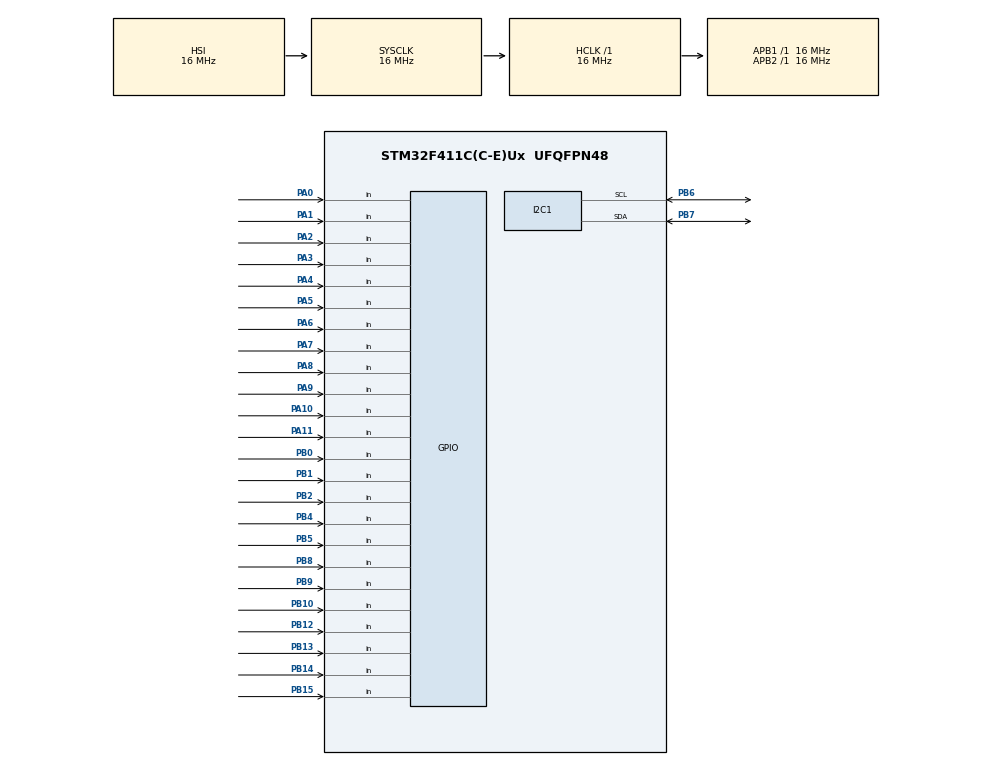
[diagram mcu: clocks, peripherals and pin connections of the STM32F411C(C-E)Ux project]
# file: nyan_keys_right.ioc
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I2C1.I2C_Mode=I2C_Fast
Mcu.Family=STM32F4
Mcu.Name=STM32F411C(C-E)Ux
Mcu.Package=UFQFPN48
NVIC.PriorityGroup=NVIC_PRIORITYGROUP_4
PA0-WKUP.GPIO_PuPd=GPIO_PULLUP
PA0-WKUP.Signal=GPIO_Input
PA1.GPIO_PuPd=GPIO_PULLUP
PA1.Signal=GPIO_Input
PA10.GPIO_PuPd=GPIO_PULLUP
PA10.Signal=GPIO_Input
PA11.GPIO_PuPd=GPIO_PULLUP
PA11.Signal=GPIO_Input
PA13.Mode=Serial_Wire
PA13.Signal=SYS_JTMS-SWDIO
PA14.Mode=Serial_Wire
PA14.Signal=SYS_JTCK-SWCLK
PA2.GPIO_PuPd=GPIO_PULLUP
PA2.Signal=GPIO_Input
PA3.GPIO_PuPd=GPIO_PULLUP
PA3.Signal=GPIO_Input
PA4.GPIO_PuPd=GPIO_PULLUP
PA4.Signal=GPIO_Input
PA5.GPIO_PuPd=GPIO_PULLUP
PA5.Signal=GPIO_Input
PA6.GPIO_PuPd=GPIO_PULLUP
PA6.Signal=GPIO_Input
PA7.GPIO_PuPd=GPIO_PULLUP
PA7.Signal=GPIO_Input
PA8.GPIO_PuPd=GPIO_PULLUP
PA8.Signal=GPIO_Input
PA9.GPIO_PuPd=GPIO_PULLUP
PA9.Signal=GPIO_Input
PB0.GPIO_PuPd=GPIO_PULLUP
PB0.Signal=GPIO_Input
PB1.GPIO_PuPd=GPIO_PULLUP
PB1.Signal=GPIO_Input
PB10.GPIO_PuPd=GPIO_PULLUP
PB10.Signal=GPIO_Input
PB12.GPIO_PuPd=GPIO_PULLUP
PB12.Signal=GPIO_Input
PB13.GPIO_PuPd=GPIO_PULLUP
PB13.Signal=GPIO_Input
PB14.GPIO_PuPd=GPIO_PULLUP
PB14.Signal=GPIO_Input
PB15.GPIO_PuPd=GPIO_PULLUP
PB15.Signal=GPIO_Input
PB2.GPIO_PuPd=GPIO_PULLUP
PB2.Signal=GPIO_Input
PB4.GPIO_PuPd=GPIO_PULLUP
PB4.Signal=GPIO_Input
PB5.GPIO_PuPd=GPIO_PULLUP
PB5.Signal=GPIO_Input
PB6.Mode=I2C
PB6.Signal=I2C1_SCL
PB7.Mode=I2C
PB7.Signal=I2C1_SDA
PB8.GPIO_PuPd=GPIO_PULLUP
PB8.Signal=GPIO_Input
PB9.GPIO_PuPd=GPIO_PULLUP
PB9.Signal=GPIO_Input
PC14-OSC32_IN.Mode=LSE-External-Oscillator
PC14-OSC32_IN.Signal=RCC_OSC32_IN
PC15-OSC32_OUT.Mode=LSE-External-Oscillator
PC15-OSC32_OUT.Signal=RCC_OSC32_OUT
PH0\ -\ OSC_IN.Mode=HSE-External-Oscillator
PH0\ -\ OSC_IN.Signal=RCC_OSC_IN
PH1\ -\ OSC_OUT.Mode=HSE-External-Oscillator
PH1\ -\ OSC_OUT.Signal=RCC_OSC_OUT
ProjectManager.HeapSize=0x200
ProjectManager.StackSize=0x400
ProjectManager.TargetToolchain=STM32CubeIDE
RCC.AHBFreq_Value=16000000
RCC.APB1Freq_Value=16000000
RCC.APB2Freq_Value=16000000
RCC.CortexFreq_Value=16000000
RCC.HSE_VALUE=25000000
RCC.HSI_VALUE=16000000
RCC.SYSCLKFreq_VALUE=16000000
RCC.VCOOutputFreq_Value=192000000
board=custom

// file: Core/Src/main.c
/* USER CODE BEGIN Header */
/**
  ******************************************************************************
  * @file           : main.c
  * @brief          : Main program body
  ******************************************************************************
  * @attention
  *
  * Copyright (c) 2025 STMicroelectronics.
  * All rights reserved.
  *
  * This software is licensed under terms that can be found in the LICENSE file
  * in the root directory of this software component.
  * If no LICENSE file comes with this software, it is provided AS-IS.
  *
  ******************************************************************************
  */
/* USER CODE END Header */
#include "main.h"

/* USER CODE BEGIN Includes */
#include "right_side_keyboard.h"
/* USER CODE END Includes */

I2C_HandleTypeDef hi2c1;

void SystemClock_Config(void);
static void MX_GPIO_Init(void);
static void MX_I2C1_Init(void);

int main(void)
{

  /* MCU Configuration--------------------------------------------------------*/

  /* Reset of all peripherals, Initializes the Flash interface and the Systick. */
  HAL_Init();
  SCB->VTOR = FLASH_BASE | 0x4000;

  /* Configure the system clock */
  SystemClock_Config();

  /* Initialize all configured peripherals */
  MX_GPIO_Init();
  MX_I2C1_Init();
  /* USER CODE BEGIN 2 */

  // Initialize the keyboard
  if (!RightKeyboardInit()) {
    Error_Handler();
  }

  /* USER CODE END 2 */

  /* Infinite loop */
  while (1)
  {

    /* USER CODE BEGIN 3 */
    // Create a local keyboard state
    RightKeyboardState state;

    // Scan the keyboard
    RightKeyboardScan6KRO(&state, 6);

    // Update the global keyboard state in case I2C callback gets triggered
    // This ensures we always have fresh key data to send
    HAL_I2C_Slave_Transmit_IT(&hi2c1, (uint8_t*)&state, sizeof(state));

    // Small delay to avoid busy-waiting and consuming too much power
    HAL_Delay(10);
  }
  /* USER CODE END 3 */
}

void SystemClock_Config(void)
{
  RCC_OscInitTypeDef RCC_OscInitStruct = {0};
  RCC_ClkInitTypeDef RCC_ClkInitStruct = {0};

  /** Configure the main internal regulator output voltage
  */
  __HAL_RCC_PWR_CLK_ENABLE();
  __HAL_PWR_VOLTAGESCALING_CONFIG(PWR_REGULATOR_VOLTAGE_SCALE1);

  /** Initializes the RCC Oscillators according to the specified parameters
  * in the RCC_OscInitTypeDef structure.
  */
  RCC_OscInitStruct.OscillatorType = RCC_OSCILLATORTYPE_HSI;
  RCC_OscInitStruct.HSIState = RCC_HSI_ON;
  RCC_OscInitStruct.HSICalibrationValue = RCC_HSICALIBRATION_DEFAULT;
  RCC_OscInitStruct.PLL.PLLState = RCC_PLL_NONE;
  if (HAL_RCC_OscConfig(&RCC_OscInitStruct) != HAL_OK)
  {
    Error_Handler();
  }

  /** Initializes the CPU, AHB and APB buses clocks
  */
  RCC_ClkInitStruct.ClockType = RCC_CLOCKTYPE_HCLK|RCC_CLOCKTYPE_SYSCLK
                              |RCC_CLOCKTYPE_PCLK1|RCC_CLOCKTYPE_PCLK2;
  RCC_ClkInitStruct.SYSCLKSource = RCC_SYSCLKSOURCE_HSI;
  RCC_ClkInitStruct.AHBCLKDivider = RCC_SYSCLK_DIV1;
  RCC_ClkInitStruct.APB1CLKDivider = RCC_HCLK_DIV1;
  RCC_ClkInitStruct.APB2CLKDivider = RCC_HCLK_DIV1;

  if (HAL_RCC_ClockConfig(&RCC_ClkInitStruct, FLASH_LATENCY_0) != HAL_OK)
  {
    Error_Handler();
  }
}

static void MX_I2C1_Init(void)
{

  hi2c1.Instance = I2C1;
  hi2c1.Init.ClockSpeed = 100000;
  hi2c1.Init.DutyCycle = I2C_DUTYCYCLE_2;
  hi2c1.Init.OwnAddress1 = RIGHT_KEYBOARD_I2C_ADDRESS << 1; // Right keyboard I2C address (shifted left for HAL)
  hi2c1.Init.AddressingMode = I2C_ADDRESSINGMODE_7BIT;
  hi2c1.Init.DualAddressMode = I2C_DUALADDRESS_DISABLE;
  hi2c1.Init.OwnAddress2 = 0;
  hi2c1.Init.GeneralCallMode = I2C_GENERALCALL_DISABLE;
  hi2c1.Init.NoStretchMode = I2C_NOSTRETCH_DISABLE;
  if (HAL_I2C_Init(&hi2c1) != HAL_OK)
  {
    Error_Handler();
  }

}

static void MX_GPIO_Init(void)
{

  /* GPIO Ports Clock Enable */
  __HAL_RCC_GPIOC_CLK_ENABLE();
  __HAL_RCC_GPIOH_CLK_ENABLE();
  __HAL_RCC_GPIOA_CLK_ENABLE();
  __HAL_RCC_GPIOB_CLK_ENABLE();

}

void Error_Handler(void)
{
  __disable_irq();
  while (1)
  {
  }
}
